# NANO100BN_v1 register map
File version: 1.0
Registers are 32-bit, read-write, reset 0x0 unless marked. A register's access mark holds for its fields unless they carry their own. Offsets are from the block's base; [hi:lo] are bit positions; 'fields as' and 'values as' point back to an identical list.

## UART0 — UART Register Map
Base 0x40050000
0x00 UART_RBR ro reset not defined — UART Receive Buffer Register.
  [7:0] RBR — Receive Buffer Register. By reading this register, the UART will return an 8-bit data received from RX pin (LSB first).
0x00 UART_THR wo reset not defined (alternate view of UART_RBR) — UART Transmit Holding Register.
  [7:0] THR — Transmit Holding Register. By writing to this register, the UART will send out an 8-bit data through the TX pin (LSB first).
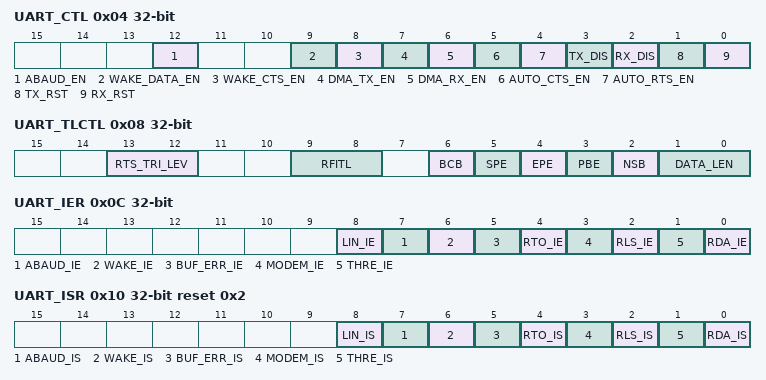
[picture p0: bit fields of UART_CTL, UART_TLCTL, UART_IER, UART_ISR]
0x04 UART_CTL — UART Control State Register.
  [12] ABAUD_EN — Auto-Baud Rate Detect Enable. Note: When the auto-baud rate detect operation finishes, hardware will clear this bit and the associated interrupt (INT_ABAUD) will be generated (If UART_IER [ABAUD_IE] be enabled).
    0=Auto-baud rate detect function Disabled; 1=Auto-baud rate detect function Enabled
  [9] WAKE_DATA_EN — Incoming Data Wake-up Function Enable. Note: Hardware will clear this bit when the incoming data wake-up operation finishes and "system clock" work stable.
    0=Incoming data wake-up system Disabled; 1=Incoming data wake-up function Enabled when the system is in power-down mode, incoming data will wake-up system from power-down mode
  [8] WAKE_CTS_EN — CTSn Wake-Up Function Enable
    0=CTSn wake-up system function Disabled; 1=Wake-up function Enabled when the system is in power-down mode, an external CTSn change will wake-up system from power-down mode
  [7] DMA_TX_EN — TX DMA Enable. This bit can enable or disable TX PDMA service.
    0=TX PDMA service function Enabled; 1=TX PDMA service function Disabled
  [6] DMA_RX_EN — RX DMA Enable. This bit can enable or disable RX PDMA service.
    0=RX PDMA service function Enabled; 1=RX PDMA service function Disabled
  [5] AUTO_CTS_EN — CTSn Auto-Flow Control Enable. Note: When CTSn auto-flow is enabled, the UART will send data to external device when CTSn input assert (UART will not send data to device until CTSn is asserted).
    0=CTSn auto-flow control. Disabled; 1=CTSn auto-flow control Enabled
  [4] AUTO_RTS_EN — RTSn Auto-Flow Control Enable. Note: When RTSn auto-flow is enabled, if the number of bytes in the RX-FIFO equals the UART_FCR [RTS_Tri_Lev], the UART will reassert RTSn signal.
    0=RTSn auto-flow control. Disabled; 1=RTSn auto-flow control Enabled
  [3] TX_DIS — Transfer Disable Register. The receiver is disabled or not (set "1" to disable receiver)
    0=Transfer Enabled; 1=Transfer Disabled
  [2] RX_DIS — Receiver Disable Register. The receiver is disabled or not (set "1" to disable receiver). Note1: When used for RS-485 NMM mode, user can set this bit to receive data before detecting address byte. Note2: In RS-485 AAD mode and LIN "break + sync +PID" header mode, hardware will control data automatically, so don't fill any value to this bit.
    0=Receiver Enabled; 1=Receiver Disabled
  [1] TX_RST — TX Software Reset. When TX_RST is set, all the bytes in the transmitting FIFO and TX internal state machine are cleared. Note: This bit will be auto cleared and take at least 3 UART engine clock cycles.
    0=No effect; 1=Reset the TX internal state machine and pointers
  [0] RX_RST — RX Software Reset. When RX_RST is set, all the bytes in the receiving FIFO and RX internal state machine are cleared. Note: This bit will be auto cleared and take at least 3 UART engine clock cycles.
    0=No effect; 1=Reset the RX internal state machine and pointers
0x08 UART_TLCTL — UART Transfer Line Control Register.
  [13:12] RTS_TRI_LEV — RTSn Trigger Level (For Auto-flow Control Use)
  [9:8] RFITL — RX-FIFO Interrupt (INT_RDA) Trigger Level
  [6] BCB — Break Control Bit. When this bit is set to logic "1", the serial data output (TX) is forced to the Spacing State (logic "0"). This bit acts only on TX pin and has no effect on the transmitter logic.
  [5] SPE — Stick Parity Enable
    0=Stick parity Disabled; 1=When bits PBE, EPE and SPE are set, the parity bit is transmitted and checked as "0". When PBE and SPE are set and EPE is cleared, the parity bit is transmitted and checked as "1". In RS-485 mode, PBE, EPE and SPE can control bit 9, the bit 9 setting are shown as follows
  [4] EPE — Even Parity Enable. Note: This bit has effect only when PBE bit (parity bit enable) is set.
    0=Odd number of logic 1's are transmitted or check the data word and parity bits in receiving mode; 1=Even number of logic 1's are transmitted or check the data word and parity bits in receiving mode
  [3] PBE — Parity Bit Enable
    0=Parity bit is not generated (transmitting data) or checked (receiving data) during transfer; 1=Parity bit is generated or checked bet"een the "last data"word "it" and "stop bit" of the serial data
  [2] NSB — Number of STOP Bit Length
    0=1 " STOP bit" is generated in the transmitted data; 1=1.5 "STOP bit" is generated in the transmitted data when 5-bit word length is selected, and 2 STOP bit" is generated when 6, 7 and 8 bits data length is selected
  [1:0] DATA_LEN — Data Length
0x0C UART_IER — UART Interrupt Enable Register.
  [8] LIN_IE — LIN Interrupt Enable
    0=INT_LIN Masked off; 1=INT_LIN Enabled
  [7] ABAUD_IE — Auto-Baud Rate Interrupt Enable
    0=INT_ABAUD Masked off; 1=INT_ABAUD Enabled
  [6] WAKE_IE — Wake-Up Interrupt Enable
    0=INT_WAKE Masked off; 1=INT_WAKE Enabled
  [5] BUF_ERR_IE — Buffer Error Interrupt Enable
    0=INT_BUT_ERR Masked off; 1=INT_BUF_ERR Enabled
  [4] RTO_IE — RX Time-Out Interrupt Enable
    0=INT_TOUT Masked off; 1=INT_TOUT Enabled
  [3] MODEM_IE — Modem Status Interrupt Enable
    0=INT_MOS Masked off; 1=INT_MOS Enabled
  [2] RLS_IE — Receive Line Status Interrupt Enable
    0=INT_RLS Masked off; 1=INT_RLS Enabled
  [1] THRE_IE — Transmit Holding Register Empty Interrupt Enable
    0=INT_THRE Masked off; 1=INT_THRE Enabled
  [0] RDA_IE — Receive Data Available Interrupt Enable
    0=INT_RDA Masked off; 1=INT_RDA Enabled
0x10 UART_ISR reset 0x2 — UART Interrupt Status Register.
  [8] LIN_IS ro — LIN Interrupt Status Flag (Read Only). This bit is set when the LIN TX header transmitted, RX header received or the SIN does not equal SOUT and if IER [LIN_IE] is set then the LIN interrupt will be generated. Note1: This bit is read only, but can be cleared by it by writing "1" to UART_TRSR [BIT_ERR_F], UART_TRSR [BIT_TX_F] or UART_TRSR [LIN_RX_F]. Note2: This bit is cleared when both the BIT_ERR_F, BIT_TX_F and LIN_RX_F are cleared.
  [7] ABAUD_IS ro — Auto-Baud Rate Interrupt Status Flag (Read Only). This bit is set when auto-baud rate detection function finished or the auto-baud rate counter was overflow and if IER [ABAUD_IE] is set then the auto-baud rate interrupt will be generated. Note1: This bit is read only, but can be cleared by it by writing "1" to UART_TRSR [ABAUD_TOUT_F] or UART_TRSR [ABAUD_F]. Note2: This bit is cleared when both the ABAUD_TOUT_F and ABAUD_F are cleared.
  [6] WAKE_IS ro — Wake-Up Interrupt Status Flag (Read Only). This bit is set in Power-down mode, the receiver received data or CTSn signal. If IER [WAKE_IE] is set then the wake-up interrupt will be generated. Note: This bit is read only, but can be cleared by it by writing "1" to it.
  [5] BUF_ERR_IS ro — Buffer Error Interrupt Status Flag (Read Only). This bit is set when the TX or RX-FIFO overflowed. When BUF_ERR_IS is set, the transfer maybe not correct. If IER [BUF_ER_IEN] is set then the buffer error interrupt will be generated. Note1: This bit is read only, but can be cleared by it by writing "1" to UART_FSR [TX_OVER_F] or UART_FSR [RX_OVER_F]. Note2: This bit is cleared when both the TX_OVER_F and RX_OVER_F are cleared.
  [4] RTO_IS ro — RX Time-Out Interrupt Status Flag (Read Only). This bit is set when the RX-FIFO is not empty and no activities occur in the RX-FIFO and the time-out counter equal to TOIC. If IER [Tout_IEN] is set then the tout interrupt will be generated. Note: This bit is read only and user can read UART_RBR (RX is in active) to clear it.
  [3] MODEM_IS ro — MODEM Interrupt Status Flag (Read Only). Note: This bit is read only, but can be cleared by it by writing "1" to UART_MCSR [DCT_F].
  [2] RLS_IS ro — Receive Line Interrupt Status Flag (Read Only). This bit is set when the RX received data has parity error (UART_FSR [PE_F]), framing error (UART_FSR [FE_F]), break error (UART_FSR [BI_F]) or RS-485 detect address byte (UART_TRSR [RS-485_ADDET_F]).If IER [RLS_IEN] is set then the RLS interrupt will be generated. Note1: This bit is read only, but can be cleared by it by writing "1" to UART_FSR [BI_F], UART_FSR [FE_F], UART_FSR [PE_F] or UART_TRSR [RS-485_ADDET_F]. Note2: This bit is cleared when both the BI_F, FE_F, PE_F and RS-485_ADDET_F are cleared.
  [1] THRE_IS ro — Transmit Holding Register Empty Interrupt Flag (Read Only). This bit is set when the last data of TX-FIFO is transferred to Transmitter Shift Register. If IER [THRE_IEN] is set that the THRE interrupt will be generated. Note: This bit is read only and it will be cleared when writing data into THR (TX-FIFO not empty).
  [0] RDA_IS ro — Receive Data Available Interrupt Flag (Read Only). When the number of bytes in the RX-FIFO equals the RFITL then the RDA_IF will be set. If IER [RDA_IEN] is set then the RDA interrupt will be generated. Note: This bit is read only and it will be cleared when the number of unread bytes of RX-FIFO drops below the threshold level (RFITL).
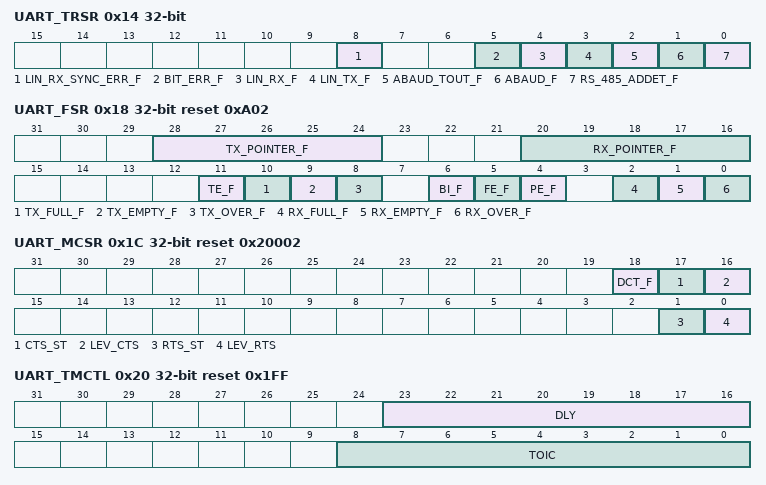
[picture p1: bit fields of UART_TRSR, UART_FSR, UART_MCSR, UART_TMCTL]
0x14 UART_TRSR — UART Transfer State Status Register.
  [8] LIN_RX_SYNC_ERR_F ro — LIN RX SYNC Error Flag (Read Only). This bit is set to logic "1" when LIN received incorrect SYNC field. User can choose the header by setting UART_ALT_CTL [LIN_HEAD_SEL] register. If the field includes "break field + sync field" and if the sync data does not equal 0x55, the LIN_RX_F and LIN_RX_SYNC_ERR_F will be set and the wrong sync data will be ignored. The controller will receive next data and put it in FIFO. If the field includes "break field + sync field + PID field" and if the sync data does not equal 0x55, the LIN_RX_F and LIN_RX_SYNC_ERR_F will be set and the wrong sync data will be ignored. The controller will receive next data and put it in FIFO. Note: This bit is read only, but can be cleared by writing "1" to LIN_RX_F.
  [5] BIT_ERR_F ro — Bit Error Detect Status Flag (Read Only). At TX transfer state, hardware will monitoring the bus state, if the input pin (SIN) state is not equal to the output pin (SOUT) state, BIT_ERR_F will be set. When occur bit error, hardware will generate an interrupt to CPU (INT_LIN). Note1: This bit is read only, but it can be cleared by writing "1" to it.
  [4] LIN_RX_F ro — LIN RX Interrupt Flag (Read Only). This bit is set to logic "1" when received LIN header field. The header may be "break field" or "break field + sync field" or "break field + sync field + PID field", and it can be choose by setting UART_ALT_CTL [LIN_HEAD_SEL] register. If the field includes "break field", when the receiver received break field then the LIN_RX_F will be set. The controller will receive next data and put it in FIFO. If the field includes "break field + sync field", hardware will wait for the flag LIN_RX_F in UART_TRSR to check RX received break field and sync field. If the break and sync field is received, hardware will set UART_TRSR [LIN_RX_F] flag, and if the break is received but the sync field does not equal 0x55, then hardware will set UART_TRSR [LIN_RX_F] and UART_TRSR [LIN_RX_SYNC_ERR_F] flag. The break and sync data (equals 0x55 or not) will not be stored in FIFO. If the field includes "break field + sync field + PID field", In this operation mode, hardware will control data automatically. Hardware will ignore any data until received break + sync (0x55) + PID value match the UART_ALT_CTL [ADDR_MATCH] value (break + sync + PID will not be stored in FIFO). When received break + sync (0x55) + PID value match the UART_ALT_CTL [ADDR_MATCH] value, hardware will set UART_TRSR [LIN_RX_F] and the following all data will be accepted and stored in the RX-FIFO until detect next break field. If the receiver received break + wrong sync (not equal 0x55) + PID value, hardware will set UART_TRSR [LIN_RX_F] and UART_TRSR [LIN_RX_SYNC_ERR_F] flag and the receiver will be disabled. If the receiver received break + sync (0x55) + wrong PID value, hardware will set UART_TRSR [LIN_RX_F] flag and the receiver will be disabled. Note: This bit is read only, but can be cleared by writing "1" to it.
  [3] LIN_TX_F ro — LIN TX Interrupt Flag (Read Only). This bit is set to logic "1" when LIN transmitted header field. The header may be "break field" or "break field + sync field" or "break field + sync field + PID field", it can be choose by setting UART_ALT_CTL[LIN_HEAD_SEL] register. Note: This bit is read only, but can be cleared by writing "1" to it.
  [2] ABAUD_TOUT_F ro — Auto-Baud Rate Time-Out Interrupt (Read Only). This bit is set to logic "1" in Auto-baud Rate Detect mode and the baud rate counter is overflow. Note: This bit is read only, but can be cleared by writing "1" to it.
  [1] ABAUD_F ro — Auto-Baud Rate Interrupt (Read Only). This bit is set to logic "1" when auto-baud rate detect function finished. Note: This bit is read only, but can be cleared by writing "1" to it.
  [0] RS_485_ADDET_F ro — RS-485 Address Byte Detection Status Flag (Read Only). Note1: This field is used for RS-485 mode. Note2: This bit is read only, but can be cleared by writing "1" to it.
0x18 UART_FSR reset 0xA02 — UART FIFO State Status Register.
  [28:24] TX_POINTER_F ro — TX-FIFO Pointer (Read Only). This field indicates the TX-FIFO Buffer Pointer. When CPU writes one byte data into UART_THR, TX_POINTER_F increases one. When one byte of TX-FIFO is transferred to Transmitter Shift Register, TX_POINTER_F decreases one.
  [20:16] RX_POINTER_F ro — RX-FIFO Pointer (Read Only). This field indicates the RX-FIFO Buffer Pointer. When UART receives one byte from external device, RX_POINTER_F increases one. When one byte of RX-FIFO is read by CPU, RX_POINTER_F decreases one.
  [11] TE_F ro — Transmitter Empty Status Flag (Read Only). Bit is set by hardware when TX is inactive. (TX shift register does not have data). Bit is cleared automatically when TX-FIFO is transfer data to TX shift register or TX is empty but the transfer does not finish.
  [10] TX_FULL_F ro — Transmitter FIFO Full (Read Only). This bit indicates TX-FIFO full or not. This bit is set when TX_POINTER_F is equal to 16, otherwise is cleared by hardware.
  [9] TX_EMPTY_F ro — Transmitter FIFO Empty (Read Only). This bit indicates TX-FIFO empty or not. When the last byte of TX-FIFO has been transferred to Transmitter Shift Register, hardware sets this bit high. It will be cleared when writing data into THR (TX-FIFO not empty).
  [8] TX_OVER_F ro — TX Overflow Error Interrupt Status Flag (Read Only). If TX-FIFO (UART_THR) is full, an additional write to UART_THR will cause this bit to logic "1". Note: This bit is read only, but it can be cleared by writing "1" to it.
  [6] BI_F ro — Break Status Flag (Read Only). This bit is set to a logic "1" whenever the received data input(RX) is held in the "spacing state" (logic "0") for longer than a full word transmission time (that is, the total time of "start bit" + data bits + parity + stop bits) and it is reset whenever the CPU writes "1" to this bit. Note: This bit is read only, but it can be cleared by writing "1" to it.
  [5] FE_F ro — Framing Error Status Flag (Read Only). This bit is set to logic "1" whenever the received character does not have a valid "stop bit" (that is, the stop bit following the last data bit or parity bit is detected as a logic "0"), and it is reset whenever the CPU writes "1" to this bit. Note: This bit is read only, but it can be cleared by writing "1" to it.
  [4] PE_F ro — Parity Error State Status Flag (Read Only). This bit is set to logic "1" whenever the received character does not have a valid "parity bit", and it is reset whenever the CPU writes "1" to this bit. Note: This bit is read only, but it can be cleared by writing "1" to it.
  [2] RX_FULL_F ro — Receiver FIFO Full (Read Only). This bit initiates RX-FIFO full or not. This bit is set when RX_POINTER_F is equal to 16, otherwise is cleared by hardware.
  [1] RX_EMPTY_F ro — Receiver FIFO Empty (Read Only). This bit initiate RX-FIFO empty or not. When the last byte of RX-FIFO has been read by CPU, hardware sets this bit high. It will be cleared when UART receives any new data.
  [0] RX_OVER_F ro — RX Overflow Error Status Flag (Read Only). This bit is set when RX-FIFO overflow. If the number of bytes of received data is greater than RX-FIFO (UART_RBR) size, 16 bytes of UART0/UART1, this bit will be set. Note: This bit is read only, but it can be cleared by writing "1" to it.
0x1C UART_MCSR reset 0x20002 — UART Modem State Status Register.
  [18] DCT_F ro — Detect CTSn State Change Status Flag (Read Only). This bit is set whenever CTSn input has change state, and it will generate Modem interrupt to CPU when UART_IER [Modem_IEN]. Note: This bit is read only, but it can be cleared by writing "1" to it.
  [17] CTS_ST ro — CTSn Pin Status (Read Only). This bit is the pin status of CTSn.
  [16] LEV_CTS — CTSn Trigger Level
    0=Low level triggered; 1=High level triggered
  [1] RTS_ST ro — RTSn Pin State (Read Only). This bit is the pin status of RTSn.
  [0] LEV_RTS — RTSn Trigger Level
    0=low level triggered; 1=high level triggered
0x20 UART_TMCTL reset 0x1FF — UART Time-Out Control State Register.
  [23:16] DLY — TX Delay Time Value. This field is use to program the transfer delay time between the last stop bit leaving the TX-FIFO and the de-assertion of by setting UART_TOR [DLY] register. . Note1: Fill all "0" to this field indicates to disable this function. Note2: The real delay value is DLY. Note3: The counting clock is baud rate clock.
  [8:0] TOIC — Time-Out Comparator. Note1: Fill all "0" to this field indicates to disable this function. Note2: The real time-out value is TOIC + 1. Note3: The counting clock is baud rate clock.
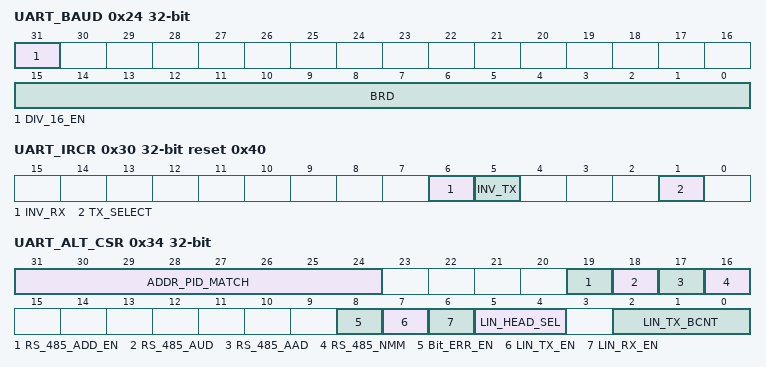
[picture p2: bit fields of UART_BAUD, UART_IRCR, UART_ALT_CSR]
0x24 UART_BAUD — UART Baud Rate Divisor Register
  [31] DIV_16_EN — Divider 16 Enable. Note: In IrDA mode, this bit must disable.
    0=The equation of baud rate is UART_CLK / [ (BRD+1)]; 1=The equation of baud rate is UART_CLK / [16 * (BRD+1)]
  [15:0] BRD — Baud Rate Divider
0x30 UART_IRCR reset 0x40 — UART IrDA Control Register.
  [6] INV_RX
    0=No inversion; 1=Inverse RX input signal
  [5] INV_TX
    0=No inversion; 1=Inverse TX output signal
  [1] TX_SELECT — TX_SELECT. Note: In IrDA mode, the UART_BAUD [DIV_16_EN) register must be set (the baud equation must be Clock / 16 * (BRD)
    0=IrDA receiver Enabled; 1=IrDA transmitter Enabled
0x34 UART_ALT_CSR — UART Alternate Control State Register.
  [31:24] ADDR_PID_MATCH — Address / PID Match Value Register. This field contains the RS-485 address match values in RS-485 Function mode. This field contains the LIN protected identifier field n LIN Function mode, software fills ID0~ID5 (ADDR_PID_MATCH [5:0]), hardware will calculate P0 and P1. . Note: This field is used for RS-485 auto address detection mode or used for LIN protected identifier field (PID).
  [19] RS_485_ADD_EN — RS-485 Address Detection Enable. Note: This field is used for RS-485 any operation mode.
    0=Address detection mode Disabled; 1=Address detection mode Enabled
  [18] RS_485_AUD — RS-485 Auto Direction Mode (RS-485 AUD Mode). Note: It can be active in RS-485_AAD or RS-485_NMM operation mode.
    0=RS-485 Auto Direction mode (AUD) Disabled; 1=RS-485 Auto Direction mode (AUD) Enabled
  [17] RS_485_AAD — RS-485 Auto Address Detection Operation Mode (RS-485 AAD Mode). Note: It can't be active in RS-485_NMM Operation mode.
    0=RS-485 Auto Address Detection Operation mode (AAD) Disabled; 1=RS-485 Auto Address Detection Operation mode (AAD) Enabled
  [16] RS_485_NMM — RS-485 Normal Multi-Drop Operation Mode (RS-485 NMM Mode). Note: It can't be active in RS-485_AAD Operation mode.
    0=RS-485 Normal Multi-drop Operation mode (NMM) Disabled; 1=RS-485 Normal Multi-drop Operation mode (NMM) Enabled
  [8] Bit_ERR_EN — Bit Error Detect Enable. Note: In LIN function mode, when bit error occurs, hardware will generate an interrupt to CPU (INT_LIN).
    0=Bit error detection function Disabled; 1=Bit error detection Enabled
  [7] LIN_TX_EN — LIN TX Header Trigger Enable. Note1: When TX header field (break field or break and sync field or break, sync and PID field) transfer operation finished, this bit will be cleared automatically and generate a interrupt to CPU (INT_LIN). Note2: If user wants to receive transmit data, it recommended to enable LIN_RX_EN bit.
    0=LIN TX Header Trigger Disabled; 1=LIN TX Header Trigger Enabled
  [6] LIN_RX_EN — LIN RX Enable. When LIN RX mode enabled and received a break field or sync field or PID field (Select by LIN_Header_SEL), the controller will generator a interrupt to CPU (INT_LIN)
    0=LIN RX mode Disabled; 1=LIN RX mode Enabled
  [5:4] LIN_HEAD_SEL — LIN Header Selection
  [2:0] LIN_TX_BCNT — LIN TX Break Field Count Register. The field contains 3-bit LIN TX break field count. Note: The break field length is LIN_TX_BCNT + 8.
0x38 UART_FUN_SEL — UART Function Select Register.
  [1:0] FUN_SEL — Function Select Enable

## UART1 — UART Register Map
Base 0x40150000
Registers as UART0; these are added or differ:
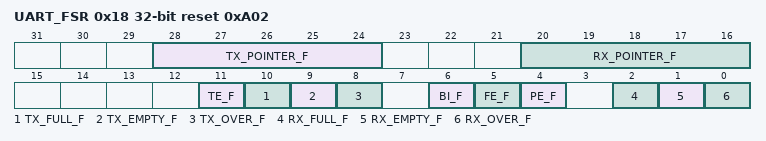
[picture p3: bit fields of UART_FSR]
0x18 UART_FSR reset 0xA02 — UART FIFO State Status Register.
  fields as UART0.UART_FSR
